# nrf7140_wificore register map
Vendor: Nordic Semiconductor; Series: nRF71; File version: 1
Registers are 32-bit, read-write, reset 0x0 unless marked. A register's access mark holds for its fields unless they carry their own. Offsets are from the block's base; [hi:lo] are bit positions; lines under a group give offsets from that group; 'fields as' and 'values as' point back to an identical list.

## RPURFBUS
Base 0x48020000
0x00 VegaGen3Dig group — Unspecified
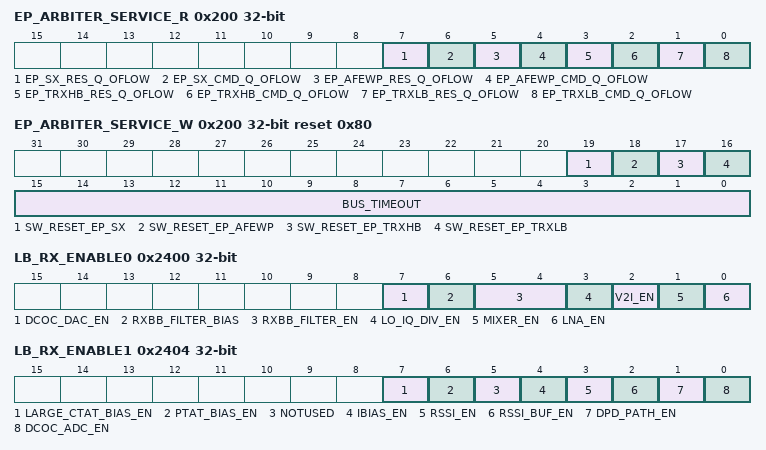
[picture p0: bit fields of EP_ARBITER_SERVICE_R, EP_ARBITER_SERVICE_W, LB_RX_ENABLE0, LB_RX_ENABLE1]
  0x200 EP_ARBITER_SERVICE_R ro — Endpoint arbiter control and status (READ)
    [7] EP_SX_RES_Q_OFLOW, [6] EP_SX_CMD_Q_OFLOW, [5] EP_AFEWP_RES_Q_OFLOW, [4] EP_AFEWP_CMD_Q_OFLOW, [3] EP_TRXHB_RES_Q_OFLOW, [2] EP_TRXHB_CMD_Q_OFLOW, [1] EP_TRXLB_RES_Q_OFLOW, [0] EP_TRXLB_CMD_Q_OFLOW
  0x200 EP_ARBITER_SERVICE_W wo reset 0x80 (alternate view of EP_ARBITER_SERVICE_R) — Endpoint arbiter control and status (WRITE)
    [19] SW_RESET_EP_SX, [18] SW_RESET_EP_AFEWP, [17] SW_RESET_EP_TRXHB, [16] SW_RESET_EP_TRXLB, [15:0] BUS_TIMEOUT
  0x2400 LB_RX_ENABLE0 — Unspecified
    [7] DCOC_DAC_EN, [6] RXBB_FILTER_BIAS, [5:4] RXBB_FILTER_EN, [3] LO_IQ_DIV_EN, [2] V2I_EN, [1] MIXER_EN, [0] LNA_EN
  0x2404 LB_RX_ENABLE1 — Unspecified
    [7] LARGE_CTAT_BIAS_EN, [6] PTAT_BIAS_EN, [5] NOTUSED, [4] IBIAS_EN, [3] RSSI_EN, [2] RSSI_BUF_EN, [1] DPD_PATH_EN, [0] DCOC_ADC_EN
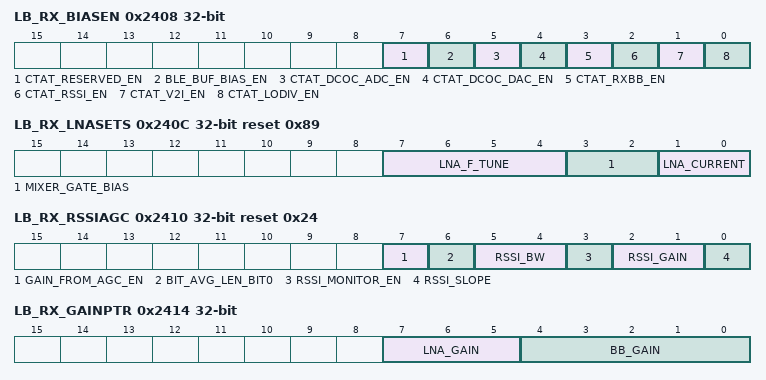
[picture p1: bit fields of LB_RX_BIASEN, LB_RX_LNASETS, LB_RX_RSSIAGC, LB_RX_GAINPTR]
  0x2408 LB_RX_BIASEN — Unspecified
    [7] CTAT_RESERVED_EN, [6] BLE_BUF_BIAS_EN, [5] CTAT_DCOC_ADC_EN, [4] CTAT_DCOC_DAC_EN, [3] CTAT_RXBB_EN, [2] CTAT_RSSI_EN, [1] CTAT_V2I_EN, [0] CTAT_LODIV_EN
  0x240C LB_RX_LNASETS reset 0x89 — Unspecified
    [7:4] LNA_F_TUNE, [3:2] MIXER_GATE_BIAS, [1:0] LNA_CURRENT
  0x2410 LB_RX_RSSIAGC reset 0x24 — Unspecified
    [7] GAIN_FROM_AGC_EN, [6] BIT_AVG_LEN_BIT0, [5:4] RSSI_BW, [3] RSSI_MONITOR_EN, [2:1] RSSI_GAIN, [0] RSSI_SLOPE
  0x2414 LB_RX_GAINPTR — Unspecified
    [7:5] LNA_GAIN, [4:0] BB_GAIN
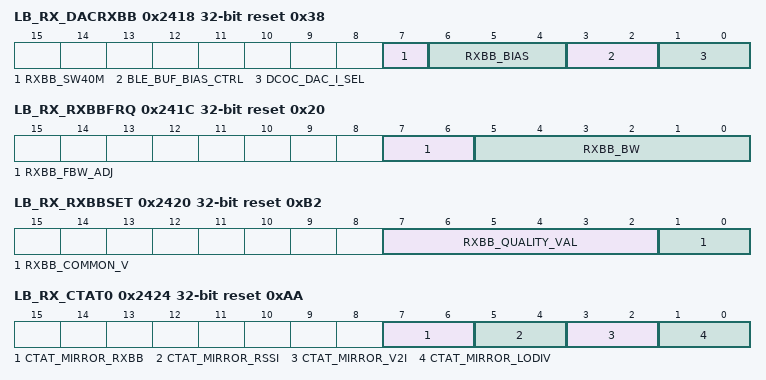
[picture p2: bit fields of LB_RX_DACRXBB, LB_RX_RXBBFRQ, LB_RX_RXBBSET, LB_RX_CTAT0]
  0x2418 LB_RX_DACRXBB reset 0x38 — Unspecified
    [7] RXBB_SW40M, [6:4] RXBB_BIAS, [3:2] BLE_BUF_BIAS_CTRL, [1:0] DCOC_DAC_I_SEL
  0x241C LB_RX_RXBBFRQ reset 0x20 — Unspecified
    [7:6] RXBB_FBW_ADJ, [5:0] RXBB_BW
  0x2420 LB_RX_RXBBSET reset 0xB2 — Unspecified
    [7:2] RXBB_QUALITY_VAL, [1:0] RXBB_COMMON_V
  0x2424 LB_RX_CTAT0 reset 0xAA — Unspecified
    [7:6] CTAT_MIRROR_RXBB, [5:4] CTAT_MIRROR_RSSI, [3:2] CTAT_MIRROR_V2I, [1:0] CTAT_MIRROR_LODIV
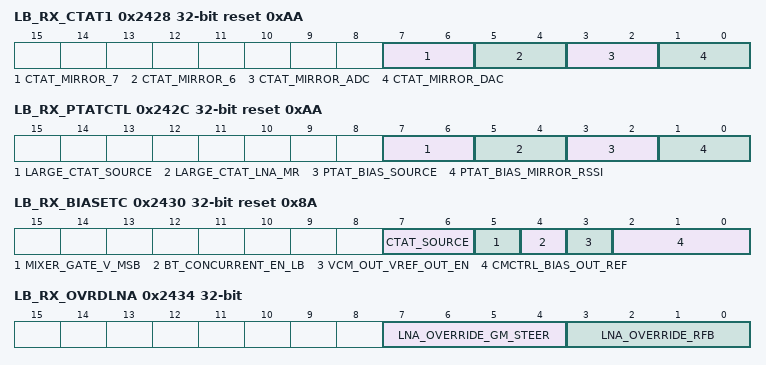
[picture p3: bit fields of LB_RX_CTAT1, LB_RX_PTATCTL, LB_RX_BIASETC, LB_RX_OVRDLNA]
  0x2428 LB_RX_CTAT1 reset 0xAA — Unspecified
    [7:6] CTAT_MIRROR_7, [5:4] CTAT_MIRROR_6, [3:2] CTAT_MIRROR_ADC, [1:0] CTAT_MIRROR_DAC
  0x242C LB_RX_PTATCTL reset 0xAA — Unspecified
    [7:6] LARGE_CTAT_SOURCE, [5:4] LARGE_CTAT_LNA_MR, [3:2] PTAT_BIAS_SOURCE, [1:0] PTAT_BIAS_MIRROR_RSSI
  0x2430 LB_RX_BIASETC reset 0x8A — Unspecified
    [7:6] CTAT_SOURCE, [5] MIXER_GATE_V_MSB, [4] BT_CONCURRENT_EN_LB, [3] VCM_OUT_VREF_OUT_EN, [2:0] CMCTRL_BIAS_OUT_REF
  0x2434 LB_RX_OVRDLNA — Unspecified
    [7:4] LNA_OVERRIDE_GM_STEER, [3:0] LNA_OVERRIDE_RFB
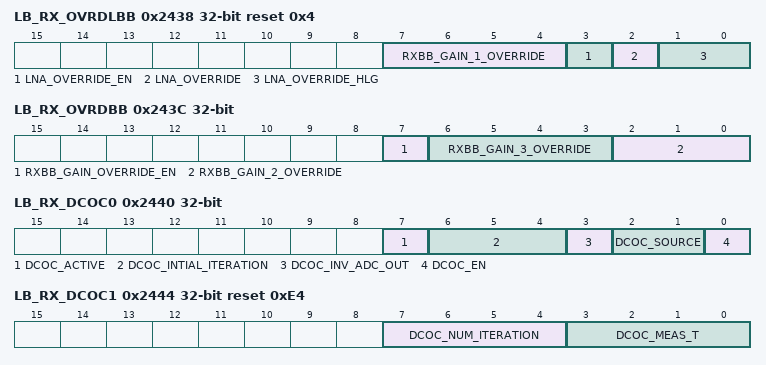
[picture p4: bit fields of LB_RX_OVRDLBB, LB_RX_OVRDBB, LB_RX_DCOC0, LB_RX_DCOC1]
  0x2438 LB_RX_OVRDLBB reset 0x4 — Unspecified
    [7:4] RXBB_GAIN_1_OVERRIDE, [3] LNA_OVERRIDE_EN, [2] LNA_OVERRIDE, [1:0] LNA_OVERRIDE_HLG
  0x243C LB_RX_OVRDBB — Unspecified
    [7] RXBB_GAIN_OVERRIDE_EN, [6:3] RXBB_GAIN_3_OVERRIDE, [2:0] RXBB_GAIN_2_OVERRIDE
  0x2440 LB_RX_DCOC0 — Unspecified
    [7] DCOC_ACTIVE ro, [6:4] DCOC_INTIAL_ITERATION, [3] DCOC_INV_ADC_OUT, [2:1] DCOC_SOURCE, [0] DCOC_EN
  0x2444 LB_RX_DCOC1 reset 0xE4 — Unspecified
    [7:4] DCOC_NUM_ITERATION, [3:0] DCOC_MEAS_T
  0x2448 LB_RX_DCOCBYPI — Unspecified
    [7:0] DCOC_I_START_BYPASS_VAL
  0x244C LB_RX_DCOCBYPQ — Unspecified
    [7:0] DCOC_Q_START_BYPASS_VAL
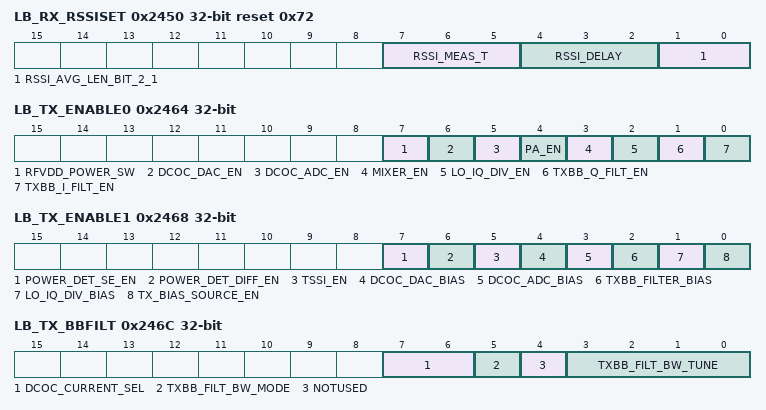
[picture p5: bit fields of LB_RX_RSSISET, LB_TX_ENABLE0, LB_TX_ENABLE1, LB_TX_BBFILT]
  0x2450 LB_RX_RSSISET reset 0x72 — Unspecified
    [7:5] RSSI_MEAS_T, [4:2] RSSI_DELAY, [1:0] RSSI_AVG_LEN_BIT_2_1
  0x2454 LB_RX_SPARE — Unspecified
    [7:0] SPARE_REG
  0x2458 LB_RX_DCOCRESI ro — Unspecified
    [7:0] DCOC_I_RESULT
  0x245C LB_RX_DCOCRESQ ro — Unspecified
    [7:0] DCOC_Q_RESULT
  0x2460 LB_RX_GAIN ro — Unspecified
    [7:0] RF_GAIN_READ
  0x2464 LB_TX_ENABLE0 — Unspecified
    [7] RFVDD_POWER_SW, [6] DCOC_DAC_EN, [5] DCOC_ADC_EN, [4] PA_EN, [3] MIXER_EN, [2] LO_IQ_DIV_EN, [1] TXBB_Q_FILT_EN, [0] TXBB_I_FILT_EN
  0x2468 LB_TX_ENABLE1 — Unspecified
    [7] POWER_DET_SE_EN, [6] POWER_DET_DIFF_EN, [5] TSSI_EN, [4] DCOC_DAC_BIAS, [3] DCOC_ADC_BIAS, [2] TXBB_FILTER_BIAS, [1] LO_IQ_DIV_BIAS, [0] TX_BIAS_SOURCE_EN
  0x246C LB_TX_BBFILT — Unspecified
    [7:6] DCOC_CURRENT_SEL, [5] TXBB_FILT_BW_MODE, [4] NOTUSED, [3:0] TXBB_FILT_BW_TUNE
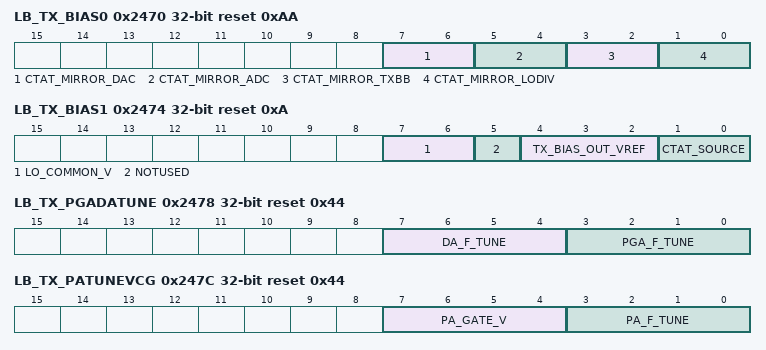
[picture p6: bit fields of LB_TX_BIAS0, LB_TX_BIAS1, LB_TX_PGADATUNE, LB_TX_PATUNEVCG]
  0x2470 LB_TX_BIAS0 reset 0xAA — Unspecified
    [7:6] CTAT_MIRROR_DAC, [5:4] CTAT_MIRROR_ADC, [3:2] CTAT_MIRROR_TXBB, [1:0] CTAT_MIRROR_LODIV
  0x2474 LB_TX_BIAS1 reset 0xA — Unspecified
    [7:6] LO_COMMON_V, [5] NOTUSED, [4:2] TX_BIAS_OUT_VREF, [1:0] CTAT_SOURCE
  0x2478 LB_TX_PGADATUNE reset 0x44 — Unspecified
    [7:4] DA_F_TUNE, [3:0] PGA_F_TUNE
  0x247C LB_TX_PATUNEVCG reset 0x44 — Unspecified
    [7:4] PA_GATE_V, [3:0] PA_F_TUNE
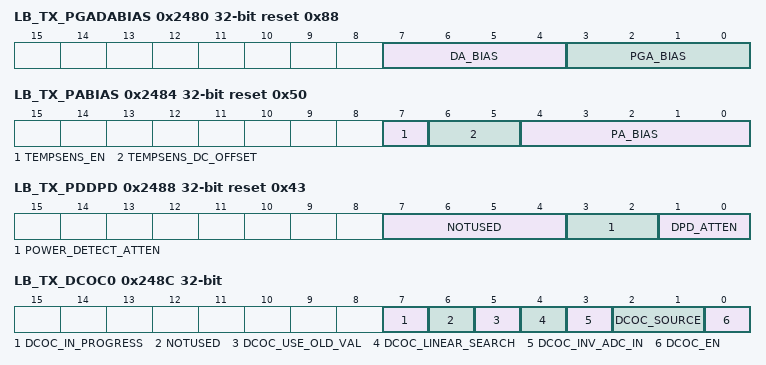
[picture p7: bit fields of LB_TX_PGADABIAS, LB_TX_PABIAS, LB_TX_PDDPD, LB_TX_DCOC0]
  0x2480 LB_TX_PGADABIAS reset 0x88 — Unspecified
    [7:4] DA_BIAS, [3:0] PGA_BIAS
  0x2484 LB_TX_PABIAS reset 0x50 — Unspecified
    [7] TEMPSENS_EN, [6:5] TEMPSENS_DC_OFFSET, [4:0] PA_BIAS
  0x2488 LB_TX_PDDPD reset 0x43 — Unspecified
    [7:4] NOTUSED, [3:2] POWER_DETECT_ATTEN, [1:0] DPD_ATTEN
  0x248C LB_TX_DCOC0 — Unspecified
    [7] DCOC_IN_PROGRESS ro, [6] NOTUSED, [5] DCOC_USE_OLD_VAL, [4] DCOC_LINEAR_SEARCH, [3] DCOC_INV_ADC_IN, [2:1] DCOC_SOURCE, [0] DCOC_EN
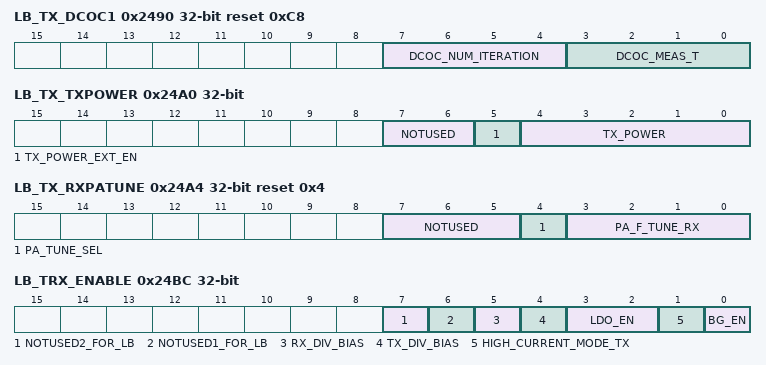
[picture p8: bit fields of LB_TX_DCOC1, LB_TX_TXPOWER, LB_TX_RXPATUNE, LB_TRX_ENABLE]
  0x2490 LB_TX_DCOC1 reset 0xC8 — Unspecified
    [7:4] DCOC_NUM_ITERATION, [3:0] DCOC_MEAS_T
  0x2494 LB_TX_DCOCBYPI — Unspecified
    [7:0] DCOC_I_START_BYPASS_VAL
  0x2498 LB_TX_DCOCBYPQ — Unspecified
    [7:0] DCOC_Q_START_BYPASS_VAL
  0x249C LB_TX_PARAMPT reset 0x20 — Unspecified
    [7:0] PA_RAMP_TIME
  0x24A0 LB_TX_TXPOWER — Unspecified
    [7:6] NOTUSED, [5] TX_POWER_EXT_EN, [4:0] TX_POWER
  0x24A4 LB_TX_RXPATUNE reset 0x4 — Unspecified
    [7:5] NOTUSED, [4] PA_TUNE_SEL, [3:0] PA_F_TUNE_RX
  0x24A8 LB_TX_SPARE — Unspecified
    [7:0] SPARE_REG
  0x24AC LB_TX_DCOCRESI ro — Unspecified
    [7:0] DCOC_I_RESULT
  0x24B0 LB_TX_DCOCRESQ ro — Unspecified
    [7:0] DCOC_Q_RESULT
  0x24B4 LB_TX_RFGAIN ro — Unspecified
    [7:0] RF_GAIN_READ
  0x24B8 LB_TX_BBGAIN ro — Unspecified
    [3:0] BB_GAIN_READ
  0x24BC LB_TRX_ENABLE — Unspecified
    [7] NOTUSED2_FOR_LB, [6] NOTUSED1_FOR_LB, [5] RX_DIV_BIAS, [4] TX_DIV_BIAS, [3:2] LDO_EN, [1] HIGH_CURRENT_MODE_TX, [0] BG_EN
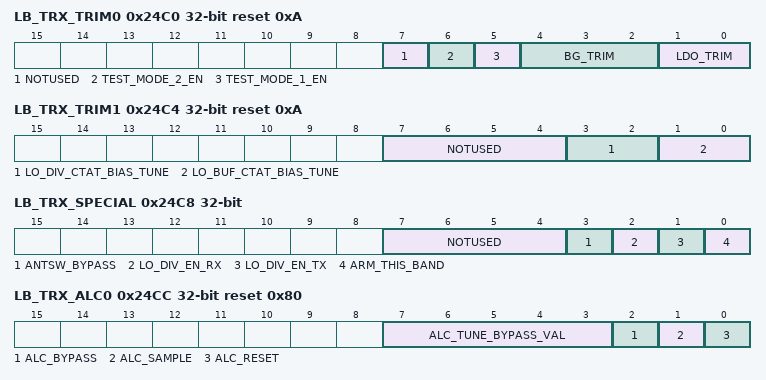
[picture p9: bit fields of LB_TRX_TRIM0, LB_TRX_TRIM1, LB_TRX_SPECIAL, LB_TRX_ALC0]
  0x24C0 LB_TRX_TRIM0 reset 0xA — Unspecified
    [7] NOTUSED, [6] TEST_MODE_2_EN, [5] TEST_MODE_1_EN, [4:2] BG_TRIM, [1:0] LDO_TRIM
  0x24C4 LB_TRX_TRIM1 reset 0xA — Unspecified
    [7:4] NOTUSED, [3:2] LO_DIV_CTAT_BIAS_TUNE, [1:0] LO_BUF_CTAT_BIAS_TUNE
  0x24C8 LB_TRX_SPECIAL — Unspecified
    [7:4] NOTUSED, [3] ANTSW_BYPASS, [2] LO_DIV_EN_RX, [1] LO_DIV_EN_TX, [0] ARM_THIS_BAND
  0x24CC LB_TRX_ALC0 reset 0x80 — Unspecified
    [7:3] ALC_TUNE_BYPASS_VAL, [2] ALC_BYPASS, [1] ALC_SAMPLE, [0] ALC_RESET
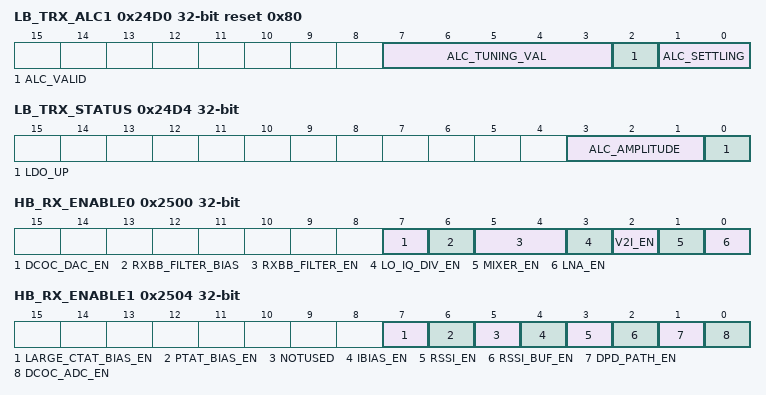
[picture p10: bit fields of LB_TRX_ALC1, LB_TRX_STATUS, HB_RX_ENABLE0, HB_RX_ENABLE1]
  0x24D0 LB_TRX_ALC1 reset 0x80 — Unspecified
    [7:3] ALC_TUNING_VAL ro, [2] ALC_VALID ro, [1:0] ALC_SETTLING
  0x24D4 LB_TRX_STATUS ro — Unspecified
    [3:1] ALC_AMPLITUDE, [0] LDO_UP
  0x2500 HB_RX_ENABLE0 — Unspecified
    fields as VegaGen3Dig.LB_RX_ENABLE0
  0x2504 HB_RX_ENABLE1 — Unspecified
    fields as VegaGen3Dig.LB_RX_ENABLE1
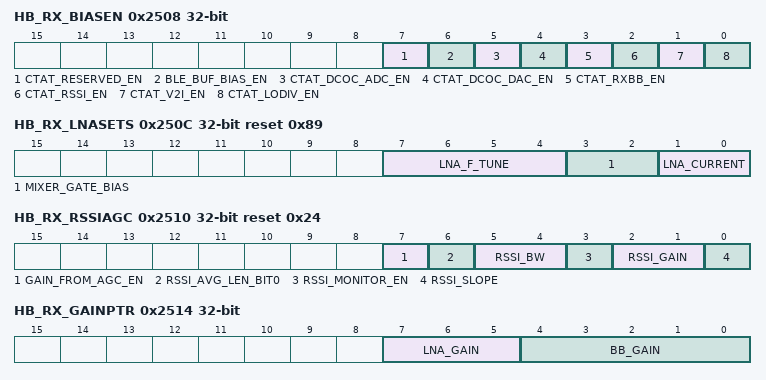
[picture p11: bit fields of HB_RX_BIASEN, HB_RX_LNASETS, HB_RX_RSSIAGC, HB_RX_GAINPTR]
  0x2508 HB_RX_BIASEN — Unspecified
    fields as VegaGen3Dig.LB_RX_BIASEN
  0x250C HB_RX_LNASETS reset 0x89 — Unspecified
    [7:4] LNA_F_TUNE, [3:2] MIXER_GATE_BIAS, [1:0] LNA_CURRENT
  0x2510 HB_RX_RSSIAGC reset 0x24 — Unspecified
    [7] GAIN_FROM_AGC_EN, [6] RSSI_AVG_LEN_BIT0, [5:4] RSSI_BW, [3] RSSI_MONITOR_EN, [2:1] RSSI_GAIN, [0] RSSI_SLOPE
  0x2514 HB_RX_GAINPTR — Unspecified
    [7:5] LNA_GAIN, [4:0] BB_GAIN
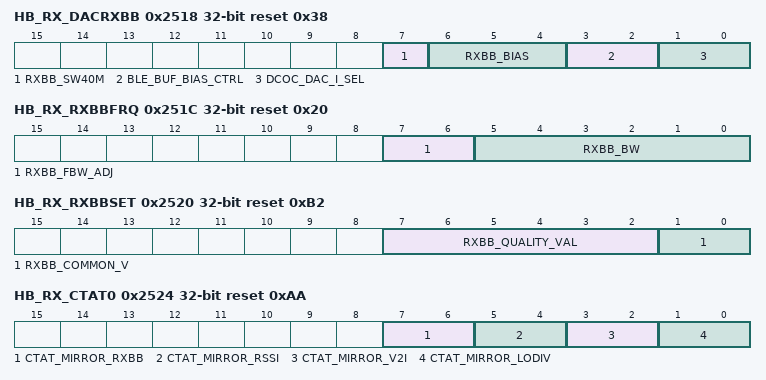
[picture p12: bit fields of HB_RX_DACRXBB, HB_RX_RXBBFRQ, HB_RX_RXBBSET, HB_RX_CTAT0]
  0x2518 HB_RX_DACRXBB reset 0x38 — Unspecified
    fields as VegaGen3Dig.LB_RX_DACRXBB
  0x251C HB_RX_RXBBFRQ reset 0x20 — Unspecified
    [7:6] RXBB_FBW_ADJ, [5:0] RXBB_BW
  0x2520 HB_RX_RXBBSET reset 0xB2 — Unspecified
    [7:2] RXBB_QUALITY_VAL, [1:0] RXBB_COMMON_V
  0x2524 HB_RX_CTAT0 reset 0xAA — Unspecified
    fields as VegaGen3Dig.LB_RX_CTAT0
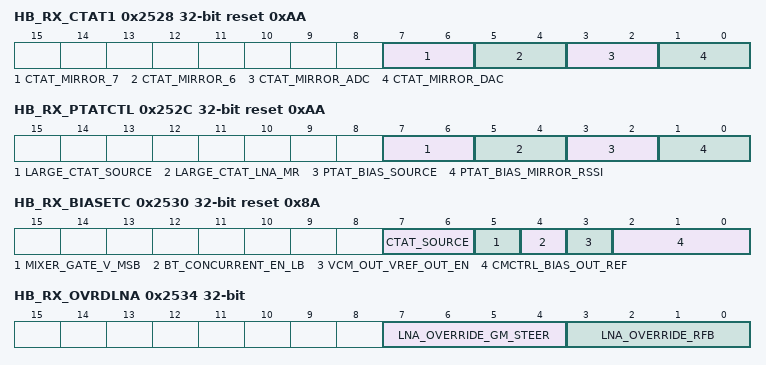
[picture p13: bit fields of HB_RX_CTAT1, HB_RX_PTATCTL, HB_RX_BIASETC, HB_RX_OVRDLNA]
  0x2528 HB_RX_CTAT1 reset 0xAA — Unspecified
    fields as VegaGen3Dig.LB_RX_CTAT1
  0x252C HB_RX_PTATCTL reset 0xAA — Unspecified
    fields as VegaGen3Dig.LB_RX_PTATCTL
  0x2530 HB_RX_BIASETC reset 0x8A — Unspecified
    fields as VegaGen3Dig.LB_RX_BIASETC
  0x2534 HB_RX_OVRDLNA — Unspecified
    [7:4] LNA_OVERRIDE_GM_STEER, [3:0] LNA_OVERRIDE_RFB
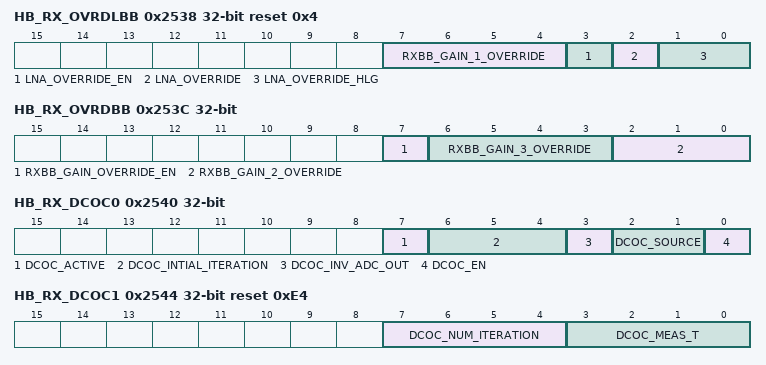
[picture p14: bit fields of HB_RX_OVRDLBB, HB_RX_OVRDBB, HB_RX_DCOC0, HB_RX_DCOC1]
  0x2538 HB_RX_OVRDLBB reset 0x4 — Unspecified
    fields as VegaGen3Dig.LB_RX_OVRDLBB
  0x253C HB_RX_OVRDBB — Unspecified
    fields as VegaGen3Dig.LB_RX_OVRDBB
  0x2540 HB_RX_DCOC0 — Unspecified
    fields as VegaGen3Dig.LB_RX_DCOC0
  0x2544 HB_RX_DCOC1 reset 0xE4 — Unspecified
    [7:4] DCOC_NUM_ITERATION, [3:0] DCOC_MEAS_T
  0x2548 HB_RX_DCOCBYPI — Unspecified
    [7:0] DCOC_I_START_BYPASS_VAL
  0x254C HB_RX_DCOCBYPQ — Unspecified
    [7:0] DCOC_Q_START_BYPASS_VAL
  0x2550 HB_RX_RSSISET reset 0x72 — Unspecified
    [7:5] RSSI_MEAS_T, [4:2] RSSI_DELAY, [1:0] RSSI_AVG_LEN_BIT_2_1
  0x2554 HB_RX_SPARE — Unspecified
    [7:0] SPARE_REG
  0x2558 HB_RX_DCOCRESI ro — Unspecified
    [7:0] DCOC_I_RESULT
  0x255C HB_RX_DCOCRESQ ro — Unspecified
    [7:0] DCOC_Q_RESULT
  0x2560 HB_RX_GAIN ro — Unspecified
    [7:0] RF_GAIN_READ
  0x2564 HB_TX_ENABLE0 — Unspecified
    fields as VegaGen3Dig.LB_TX_ENABLE0
  0x2568 HB_TX_ENABLE1 — Unspecified
    fields as VegaGen3Dig.LB_TX_ENABLE1
  0x256C HB_TX_BBFILT — Unspecified
    fields as VegaGen3Dig.LB_TX_BBFILT
  0x2570 HB_TX_BIAS0 reset 0xAA — Unspecified
    fields as VegaGen3Dig.LB_TX_BIAS0
  0x2574 HB_TX_BIAS1 reset 0xA — Unspecified
    fields as VegaGen3Dig.LB_TX_BIAS1
  0x2578 HB_TX_PGADATUNE reset 0x44 — Unspecified
    [7:4] DA_F_TUNE, [3:0] PGA_F_TUNE
  0x257C HB_TX_PATUNEVCG reset 0x44 — Unspecified
    [7:4] PA_GATE_V, [3:0] PA_F_TUNE
  0x2580 HB_TX_PGADABIAS reset 0x88 — Unspecified
    [7:4] DA_BIAS, [3:0] PGA_BIAS
  0x2584 HB_TX_PABIAS reset 0x50 — Unspecified
    [7] TEMPSENS_EN, [6:5] TEMPSENS_DC_OFFSET, [4:0] PA_BIAS
  0x2588 HB_TX_PDDPD reset 0x43 — Unspecified
    [7:4] NOTUSED, [3:2] POWER_DETECT_ATTEN, [1:0] DPD_ATTEN
  0x258C HB_TX_DCOC0 — Unspecified
    fields as VegaGen3Dig.LB_TX_DCOC0
  0x2590 HB_TX_DCOC1 reset 0xC8 — Unspecified
    [7:4] DCOC_NUM_ITERATION, [3:0] DCOC_MEAS_T
  0x2594 HB_TX_DCOCBYPI — Unspecified
    [7:0] DCOC_I_START_BYPASS_VAL
  0x2598 HB_TX_DCOCBYPQ — Unspecified
    [7:0] DCOC_Q_START_BYPASS_VAL
  0x259C HB_TX_PARAMPT reset 0x20 — Unspecified
    [7:0] PA_RAMP_TIME
  0x25A0 HB_TX_TXPOWER — Unspecified
    [7:6] NOTUSED, [5] TX_POWER_EXT_EN, [4:0] TX_POWER
  0x25A4 HB_TX_RXPATUNE reset 0x4 — Unspecified
    [7:5] NOTUSED, [4] PA_TUNE_SEL, [3:0] PA_F_TUNE_RX
  0x25A8 HB_TX_SPARE — Unspecified
    [7:0] SPARE_REG
  0x25AC HB_TX_DCOCRESI ro — Unspecified
    [7:0] DCOC_I_RESULT
  0x25B0 HB_TX_DCOCRESQ ro — Unspecified
    [7:0] DCOC_Q_RESULT
  0x25B4 HB_TX_RFGAIN ro — Unspecified
    [7:0] RF_GAIN_READ
  0x25B8 HB_TX_BBGAIN ro — Unspecified
    [3:0] BB_GAIN_READ
  0x25BC HB_TRX_ENABLE — Unspecified
    [7] ALC_ENABLE, [6] LO_DRIVER_EN, [5] NOTUSED_FOR_HB, [4] LO_BUFFER_BIAS, [3:2] LDO_EN, [1] HIGH_CURRENT_MODE_TX, [0] BG_EN
  0x25C0 HB_TRX_TRIM0 reset 0xA — Unspecified
    fields as VegaGen3Dig.LB_TRX_TRIM0
  0x25C4 HB_TRX_TRIM1 reset 0xA — Unspecified
    fields as VegaGen3Dig.LB_TRX_TRIM1
  0x25C8 HB_TRX_SPECIAL — Unspecified
    [7:3] NOTUSED, [2] NOTUSED2_FOR_HB, [1] NOTUSED1_FOR_HB, [0] ARM_THIS_BAND
  0x25CC HB_TRX_ALC0 reset 0x80 — Unspecified
    fields as VegaGen3Dig.LB_TRX_ALC0
  0x25D0 HB_TRX_ALC1 reset 0x80 — Unspecified
    [7:3] ALC_TUNING_VAL ro, [2] ALC_VALID ro, [1:0] ALC_SETTLING
  0x25D4 HB_TRX_STATUS ro — Unspecified
    [3:1] ALC_AMPLITUDE, [0] LDO_UP
  0x2600 AFE_ENABLE0 reset 0x80 — Unspecified
    [7] BG_SET_1P1V, [6] BBPLL_DAC_CLK_EN, [5] BBPLL_ADC_CLK_EN, [4] BBPLL_EN, [3] CLK_DOUBLER_EN, [2] BG_EN, [1] AFEPWR_LDO_EN, [0] AFEPWR_BG_EN
  0x2604 AFE_ENABLE1 — Unspecified
    [7] DIV_BY_7_EN, [6] LOCK_DETECT_EN, [5] TXDAC_REF_EN, [4] TXDAC_EN, [3] RXDAC_Q_REF_EN, [2] RXDAC_Q_EN, [1] RXDAC_I_REF_EN, [0] RXDAC_I_EN
  0x2608 AFE_ENABLE2 reset 0xA — Unspecified
    [7:5] LDO_TRIM, [4:2] BG_TRIM, [1:0] EN_AFEVDD_EN_BUCKDD
  0x260C AFE_TESTMUX — Unspecified
    [7] NOTUSED, [6:5] GEN3_DTB_SEL, [3:2] GEN3_ATB_SEL, [1] AFEPWR_TP1_EN, [0] AFEPWR_TP2_EN
  0x2610 AFE_AFEBG reset 0x3 — Unspecified
    [7] NOTUSED, [6:4] BG_TEST_OUT_SEL, [3] BG_TEST_OUT_EN, [2:0] BG_V_SETTING
  0x2614 AFE_BBPLL1 — Unspecified
    [7] BBPLL_DIVR_MANUAL_EN, [6] BBPLL_DIVN_MANUAL_EN, [5] BBPLL_CP_MANUAL_EN, [4] BBPLL_CC0_MANUAL_EN, [3] BBPLL_OPA_MANUAL_EN, [2] BBPLL_CCOBUF_MANUAL_EN, [1] BBPLL_AFC_MANUAL_EN, [0] BBPLL_MANUAL_EN
  0x2618 AFE_BBPLL2 reset 0x33 — Unspecified
    [7] LDO2_MANUAL_EN, [6:4] LDO2_CCO_V_SEL, [3] LDO1_MANUAL_EN, [2:0] LDO1_DIVN_V_SEL
  0x261C AFE_BBPLL3 reset 0x10 — Unspecified
    [7:5] NOTUSED, [4:2] DIV_CLK_LVDS_CTRL, [1] DIV_CLK_LVDS_EN, [0] PLL_REF_EN
  0x2620 AFE_BBPLL4 reset 0x56 — Unspecified
    [7:4] LPF_C2_SEL, [3:0] LPF_C1_SEL
  0x2624 AFE_BBPLL5 reset 0x85 — Unspecified
    [7:4] ICP_SEL, [3:0] LPF_R1_SEL
  0x2628 AFE_BBPLL6 reset 0xA0 — Unspecified
    [7:6] TP_CLK_SEL, [5:0] CCO_CAP_BANK
  0x262C AFE_BBPLL7 reset 0x14 — Unspecified
    [7] DIVN_MANUAL_EN, [6:0] DIVN
  0x2630 AFE_BBPLL8 — Unspecified
    [7] TP2_DECODER_EN, [6:4] TP2_DECODER_SEL, [3] TP1_DECODER_EN, [2:0] TP1_DECODER_SEL
  0x2634 AFE_BBPLL9 reset 0xC0 — Unspecified
    [7] TP_DIGCLK_SEL, [6:4] CCO_KVCO_SEL, [3:0] LDO_BYPASS_MODE
  0x2638 AFE_BBPLLA reset 0x13 — Unspecified
    [7:6] NOTUSED, [5:3] ADC_CLK_SEL, [2:0] DAC_CLK_SEL
  0x263C AFE_BBPLLB reset 0x1C — Unspecified
    [7] DIG_TP_EN, [6] DIV17_EN, [5:3] X2_COMPARATOR, [2:0] LOCK_DETECT_TIMING
  0x2640 AFE_RXADC0 reset 0x44 — Unspecified
    [7] OUTPUT_ON_CLK_FALL, [6:4] ADC_CORE_LDO_V, [3] VREF_CORE_LDO_BYPASS, [2:0] ADC_VREF_LDO_V
  0x2644 AFE_RXADC1 reset 0xFB — Unspecified
    [7] ADC_CLK_OUT_EN, [6] SIGN_MAG_OUTPUT_FORMAT, [5:4] ADC_CHANNEL_SEL, [3] TIME_INTERLEAVE_MODE, [2:0] VREF_V
  0x2648 AFE_RXADC2 reset 0x68 — Unspecified
    [7:6] VREF_CODE_LDO_BIAS, [5:4] ADC_COMMON_MODE_V_SEL, [3] DOWNSAMPLE_BY_5, [2] DOWNSAMPLE_EN, [1] ADC_TCLK_CK, [0] MIN_SAMPLING_TIME_EN
  0x264C AFE_RXADC3 reset 0x38 — Unspecified
    [7] CORE_LDO_STANDBY_V_SEL, [6:4] ADC_SPEED_SEL, [3] USE_REF_EN_INPUT, [2:0] VREF_LDO_TEST_OUT_SEL
  0x2650 AFE_RXADC4 reset 0x10 — Unspecified
    [7:5] NOTUSED, [4] RG_IN_CR_BW18, [3:0] TEST_OUT_CLK_SEL
  0x2654 AFE_TXDAC0 reset 0xB3 — Unspecified
    [7] DAC_IN_RISING_EDGE_LATCH, [6:4] DAC_LDO_V, [3] DAC_INPUT_SIGN_MAG_FORMAT, [2:0] DAC_LATCH_V
  0x2658 AFE_TXDAC1 reset 0xCC — Unspecified
    [7] Q_BIAS_EN, [6:4] Q_CASCADE_BIAS, [3] I_BIAS_EN, [2:0] I_CASCADE_BIAS
  0x265C AFE_TXDAC2 reset 0x7C — Unspecified
    [7] TEST_OUTPUT_EN, [6:4] TEST_NODE_SELECT, [3] USE_INTERNAL_BBPLL_CLK, [2] CLOCK_OUTPUT_EN, [1:0] DAC_CHANNEL_FOR_CLK
  0x2660 AFE_TXDAC3 reset 0x44 — Unspecified
    [7] DIG_BYPASS, [6:4] Q_COMMON_MODE_V, [3] LDO_BYPASS, [2:0] I_COMMON_MODE_V
  0x2664 AFE_TXDAC4 reset 0xC0 — Unspecified
    [7] I_OFFSET_EN, [6:0] I_OFFSET
  0x2668 AFE_TXDAC5 reset 0xC0 — Unspecified
    [7] Q_OFFSET_EN, [6:0] Q_OFFSET
  0x266C AFE_TXDAC6 reset 0x55 — Unspecified
    [7:6] LDO_DIG_BIAS_CURRENT_SEL, [5:4] LDO_L_BIAS_CURRENT_SEL, [3:2] Q_LOAD_RESISTOR_SEL, [1:0] I_LOAD_RESISTOR_SEL
  0x2670 AFE_TXDAC7 reset 0x88 — Unspecified
    [7] I_LOAD_RESISTANCE_EN, [6:4] I_GAIN_FINE_TUNE, [3] Q_LOAD_RESISTANCE_EN, [2:0] Q_GAIN_FINE_TUNE
  0x2674 WLP_ENABLE0 — Unspecified
    [7] BG_TRIM_4, [6] NOTUSED, [5] PALDO_LP_MODE_EN, [4] PALDO_BYPASS, [3] PALDO_EN, [2] PALDO_SOFTSTART, [1] RF_LDO_EN, [0] BG_EN
  0x2678 WLP_ENABLE1 — Unspecified
    [7] NOTUSED2, [6] TEST_MODE_2_EN, [5] TEST_MODE_1_EN, [4] PA_RFVDD_SWITCH_HB, [3] PA_RFVDD_SWITCH_LB, [2:0] NOTUSED1
  0x267C WLP_TRIM reset 0xCE — Unspecified
    [7:5] PALDO_TRIM, [4:2] RF_LDO_TRIM, [1:0] BG_TRIM
  0x2680 AFEWLP_SPARE — Unspecified
    [7:0] SPARE_REG
  0x2684 WLP_VDDUP ro — Unspecified
    [1] PALDO_UP, [0] RF_LDO_UP
  0x2688 AFE_ROBBPLL ro — Unspecified
    [7] BBPLL_LOCK_DETECT, [6] BBPLL_AFC_CAL_EN, [5:0] BBPLL_VCO_CAP_SETTING
  0x2700 SX_ENABLE0 — Unspecified
    [7:6] VDDDTC_LDO_EN, [5:4] VDDLO_LDO_EN, [3:2] SXVCO_LDO_EN, [1] FILTER_BYPASS, [0] BG_REF_EN
  0x2704 SX_ENABLE1 — Unspecified
    [7] ADPLL_STATE_MACHINE_START, [6] DCO_EN, [5] BBPLL_ENABLE_CLK, [4] TDC_POWERUP, [3:2] VDDDIG_LDO_EN, [1:0] VDDDPQ_LDO_EN
  0x2708 SX_TRIM0 reset 0x2A — Unspecified
    [7:6] VDDDTC_OUT, [5:4] VDDLO_OUT, [3:2] VDDVCO_OUT, [1:0] BG_TEMP_COEFF
  0x270C SX_TRIM1 reset 0x40 — Unspecified
    [7:4] DCO_BIAS, [3:2] VDDDIG_OUT, [1:0] VDDPQ_OUT
  0x2710 SX_LOGEN reset 0x80 — Unspecified
    [7] SAMPLE_PHASE_SEL, [6] SX_TRIM0_SELECTOR_BIT2, [5:4] LOGEN_BIAS, [1] LOGEN_EN_1, [0] LOGEN_EN_0
  0x2714 SX_ALCBP reset 0x10 — Unspecified
    [7:5] NOTUSED, [4:0] ALC_LO_TUNE_BYPASS
  0x2718 SX_TESTSEL — Unspecified
    [7] RESETN_ADPLL_BUSSCHEDULER, [6:4] DTE_SELECTOR, [3:0] ATE_SELECTOR
  0x271C SX_DEBUG — Unspecified
    [7:5] TDC_DEBUG, [4:1] DTC_DEBUG, [0] NOTUSED
  0x2720 SX_SPARE — Unspecified
    [7:0] SAPRE_REG
  0x2724 SX_ALCCTRL reset 0x4 — Unspecified
    [7:5] NOTUSED3, [4:3] ALC_SETTLING, [2] NOTUSED1, [1] ALC_SAMPLE, [0] ALC_RESET
  0x2728 SX_ALCRESULT ro reset 0x80 — Unspecified
    [11:9] ALC_VALID, [8] ALC_FINISHED, [7:3] ALC_TUNING_VAL, [2:0] ALC_RESULT
  0x272C SX_LDOUP ro — Unspecified
    [5] ADPLL_LOCK_STATUS, [4] VDDVCO_LDO_READY, [3] VDDLO_LDO_READY, [2] VDDDTC_LDO_READY, [1] VDDPQ_LDO_READY, [0] VDDDIG_LDO_READY
  0x2730 SX_CHIPID ro reset 0x230307 — Unspecified
    [23:0] CHIP_ID_DATE
0x10000 RF_CTRL group — Unspecified
  0x00 AXIMASTERACCESS reset 0x1 — RF CTRL AXI MASTER ACCESS
    [6:4] MASTERID — When RESTRICTED=1 select master with access to RF slave registers:
      0=RiscVCpu0; 1=RiscVCpu1; 2=MemoryVectorDma; 3=GlobalDomainMaster; 4=Ensigma DMA Controller RAM Read; 5=DmaControlProcessor; 6=EnsigmaDmaController6 (Ensigma DMA Controller Peripherical); 7=EnsigmaDmaController7 (Ensigma DMA Controller RAM Write)
    [0] RESTRICTED — Enable restricted access to RF slave registers:
      0=UnrestrictedAccess; 1=Restrict access to master specified by MASTER_ID
